# ADSP-2183xW_HPC register map
Vendor: Analog Devices; Series: ADSP-2183xW_HPC; File version: 3.0.3.517
CPU: 
Registers are 32-bit, read-write, reset 0x0 unless marked. A register's access mark holds for its fields unless they carry their own. Offsets are from the block's base; [hi:lo] are bit positions; {n}, {i} and the like mark numbered series.

## XSPI — Expanded Serial Peripheral Interface
Base 0x3101C000
{0x0+4i} CMD{i} (i=0..5) — Command Register {i}
  [31:0] VALUE range 0x00000000..0xFFFFFFFF — Command {i} Value
0x40 CMD_STAT_PTR — Command Status Pointer Register
  [2:0] THRD_SEL range 0x00000000..0x00000007 — Thread ID
0x44 CMD_STAT — Command Status Register
  [31:0] STAT ro — Command Status
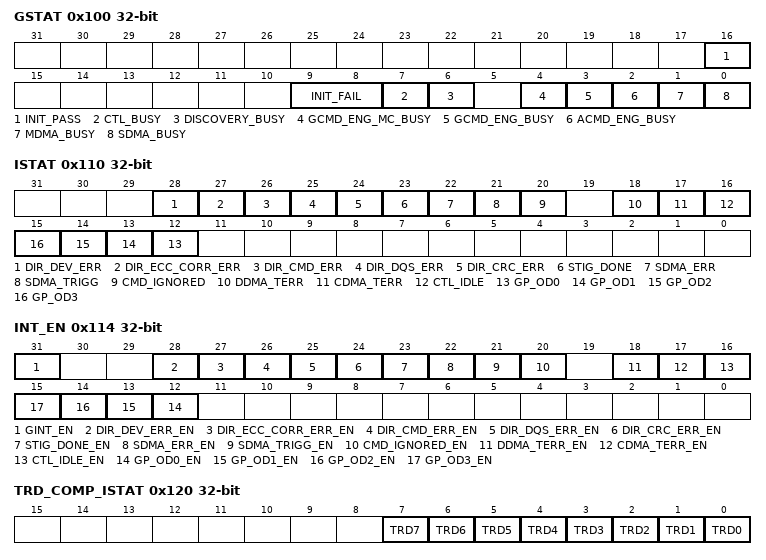
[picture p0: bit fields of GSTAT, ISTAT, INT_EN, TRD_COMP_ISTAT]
0x100 GSTAT — General Controller Status Register
  [16] INIT_PASS ro — Initialization Complete
  [9:8] INIT_FAIL ro — Initialization Status
  [7] CTL_BUSY ro — Controller Busy
  [6] DISCOVERY_BUSY ro
  [4] GCMD_ENG_MC_BUSY ro — GCMD Engine MC Busy
  [3] GCMD_ENG_BUSY ro — GCMD Engine Busy
  [2] ACMD_ENG_BUSY ro — ACMD Engine Busy
  [1] MDMA_BUSY ro
  [0] SDMA_BUSY ro
0x104 TRD_STAT — Auto Command Engine Thread Status Register
  [7:0] TRD_BUSY ro — Thread ID Busy
0x110 ISTAT — Interrupt Status Register
  [28] DIR_DEV_ERR range 0x00000000..0x00000001 — Device Return or Uncorrectable ECC Error
  [27] DIR_ECC_CORR_ERR range 0x00000000..0x00000001 — Correctable ECC Error
  [26] DIR_CMD_ERR range 0x00000000..0x00000001 — Command Error
  [25] DIR_DQS_ERR range 0x00000000..0x00000001 — DQS Error
  [24] DIR_CRC_ERR range 0x00000000..0x00000001 — CRC Error
  [23] STIG_DONE range 0x00000000..0x00000001
  [22] SDMA_ERR range 0x00000000..0x00000001 — SDMA Error
  [21] SDMA_TRIGG range 0x00000000..0x00000001 — SDMA Trigger
  [20] CMD_IGNORED range 0x00000000..0x00000001 — Command Ignored
  [18] DDMA_TERR range 0x00000000..0x00000001 — Master Data DMA Error
  [17] CDMA_TERR range 0x00000000..0x00000001 — Command DMA Error
  [16] CTL_IDLE range 0x00000000..0x00000001 — xSPI Controller Idle
  [n+12] GP_OD{n} range 0x00000000..0x00000001 (n=0..3) — GP OD{n} Transition Status
0x114 INT_EN — Interrupt Enable Register
  [31] GINT_EN range 0x00000000..0x00000001 — Global Interrupt Enable Flag
  [28] DIR_DEV_ERR_EN range 0x00000000..0x00000001 — Interrupt Enable for Uncorrectable ECC Error
  [27] DIR_ECC_CORR_ERR_EN range 0x00000000..0x00000001 — Interrupt Enable for Correctable ECC Error
  [26] DIR_CMD_ERR_EN range 0x00000000..0x00000001 — Interrupt Enable for Command Error
  [25] DIR_DQS_ERR_EN range 0x00000000..0x00000001 — Interrupt Enable for DQS Error
  [24] DIR_CRC_ERR_EN range 0x00000000..0x00000001 — Interrupt Enable for CRC Error
  [23] STIG_DONE_EN range 0x00000000..0x00000001 — Interrupt Enable for STIG Done
  [22] SDMA_ERR_EN range 0x00000000..0x00000001 — Interrupt Enable for SDMA Error
  [21] SDMA_TRIGG_EN range 0x00000000..0x00000001 — Interrupt Enable for SDMA Trigger
  [20] CMD_IGNORED_EN range 0x00000000..0x00000001 — Interrupt Enable for Ignored Command
  [18] DDMA_TERR_EN range 0x00000000..0x00000001 — Interrupt Enable for Data DMA Error
  [17] CDMA_TERR_EN range 0x00000000..0x00000001 — Interrupt Enable for Command DMA Error
  [16] CTL_IDLE_EN range 0x00000000..0x00000001 — Interrupt Enable for Idle State
  [n+12] GP_OD{n}_EN range 0x00000000..0x00000001 (n=0..3) — Interrupt Enable for GP OD{n} Transition
0x120 TRD_COMP_ISTAT — Auto Command Engine Interrupt Status Thread Register
  [n] TRD{n} range 0x00000000..0x00000001 (n=0..7) — Thread {n} Operation Complete
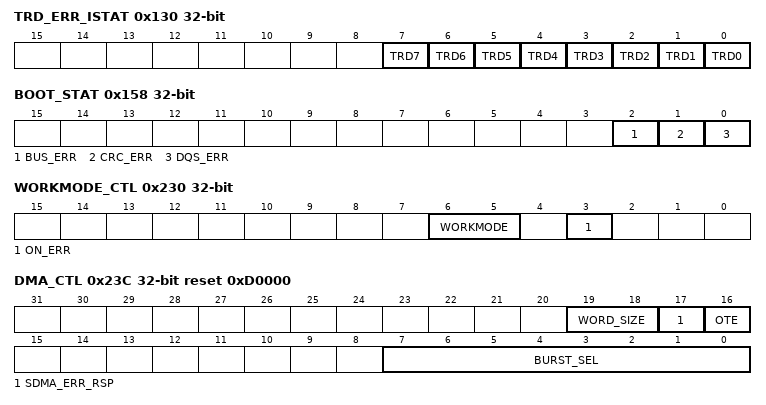
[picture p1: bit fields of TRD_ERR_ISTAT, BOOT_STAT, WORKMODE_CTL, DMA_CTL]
0x130 TRD_ERR_ISTAT — Thread Error Interrupt Status Register
  [n] TRD{n} range 0x00000000..0x00000001 (n=0..7) — Thread {n} Error
0x134 TRD_ERR_INT_EN — Thread Error Interrupt Enable Register
  [7:0] TRD_ERR_INT_EN range 0x00000000..0x000000FF — Interrupt Enable for Thread Error
0x150 DMA_ERRADDR_LO — DMA Error Address Low Register
  [31:0] VALUE ro — Low Address Value
0x154 DMA_ERRADDR_HI — DMA Error Address High Register
  [31:0] VALUE ro — High Address Value
0x158 BOOT_STAT — Boot Status Register
  [2] BUS_ERR ro — Bus Error Status
    0=BUSNOERROR (No Error Detected); 1=BUSERROR (Error Detected)
  [1] CRC_ERR ro — CRC Error Status
    0=CRCNOERROR (No Error Detected); 1=CRCERROR (Error Detected)
  [0] DQS_ERR ro — DQS Error Status
    0=DQSNOERROR (No Error Detected); 1=DQSERROR (Error Detected)
0x208 LONGPOL_GCTL reset 0x3E8 — Long Polling Count Register
  [15:0] VALUE range 0x00000000..0x0000FFFF — Long Poll Value
0x20C SHORTPOL_GCTL reset 0x1F4 — Short Polling Count Register
  [15:0] VALUE range 0x00000000..0x0000FFFF — Short Poll Value
0x230 WORKMODE_CTL — Device Control Register
  [6:5] WORKMODE range 0x00000000..0x00000003 — Controller Work Mode
  [3] ON_ERR range 0x00000000..0x00000001 — Controller On Error
0x23C DMA_CTL reset 0xD0000 — DMA Interface Control Register
  [19:18] WORD_SIZE — DMA Word Size
  [17] SDMA_ERR_RSP range 0x00000000..0x00000001 — SDMA Error Response
  [16] OTE range 0x00000000..0x00000001 — Outstanding Transaction Enable
  [7:0] BURST_SEL range 0x00000000..0x000000FF — Burst Size
0x240 SDMA_SIZ — Host DMA Block Size Register
  [31:0] VALUE ro — SDMA Block Size
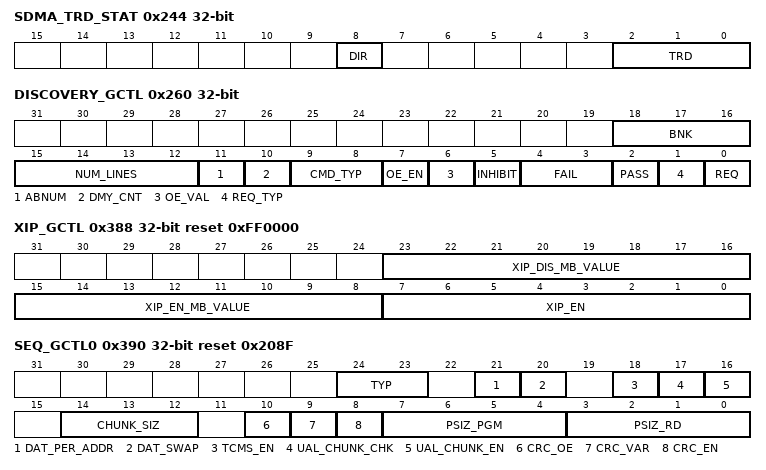
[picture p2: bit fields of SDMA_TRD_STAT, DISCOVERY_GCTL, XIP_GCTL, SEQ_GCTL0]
0x244 SDMA_TRD_STAT — Host DMA Thread Status Register
  [8] DIR ro — DMA Direction
  [2:0] TRD ro — Thread ID
0x24C SDMA_ADDR0 — Host DMA Buffer Address Register 0
  [31:0] LO_VALUE ro — Low Address Value
0x250 SDMA_ADDR1 — Host DMA Buffer Address Register 1
  [31:0] HI_VALUE ro — High Address Value
0x260 DISCOVERY_GCTL — Device Discovery Control Register
  [18:16] BNK range 0x00000000..0x00000007 — Discovery Bank Select
  [15:12] NUM_LINES — Discovery IO Number of Lines
  [11] ABNUM — Discovery Number Address
  [10] DMY_CNT — Discovery Dummy Clock Cycles Count
  [9:8] CMD_TYP — Discovery Command Type Mode Enable
  [7] OE_EN — Discovery Extended Opcode Enable
  [6] OE_VAL — Discovery Extended Opcode Value
  [5] INHIBIT ro — Discovery Inhibit Status
  [4:3] FAIL ro — Result of Last Discovery Operation
  [2] PASS ro — Status of Last Discovery Operation
  [1] REQ_TYP — Discovery Request Type
  [0] REQ range 0x00000000..0x00000001 — Discovery Request
0x388 XIP_GCTL reset 0xFF0000 — XIP Configuration Register
  [23:16] XIP_DIS_MB_VALUE range 0x00000000..0x000000FF — XIP Mode Bit Disable Value
  [15:8] XIP_EN_MB_VALUE range 0x00000000..0x000000FF — XIP Mode Bit Enable Value
  [7:0] XIP_EN range 0x00000000..0x000000FF — XIP Mode Enable
0x390 SEQ_GCTL0 reset 0x208F — Sequence Configuration Register 0
  [24:23] TYP — Sequence Type
  [21] DAT_PER_ADDR — Data Bytes per Address
  [20] DAT_SWAP — Enable Reversed Byte Order
  [18] TCMS_EN — Enable TCMS Timing in Profile 1
  [17] UAL_CHUNK_CHK — Enable CRC Checking of Unaligned Chunk
  [16] UAL_CHUNK_EN — Enable CRC Chunk
  [14:12] CHUNK_SIZ — Chunk Size
  [10] CRC_OE
  [9] CRC_VAR — Select CRC Variant
  [8] CRC_EN — Enable CRC
  [7:4] PSIZ_PGM range 0x00000000..0x0000000F — Device Page Program Size
  [3:0] PSIZ_RD range 0x00000000..0x0000000F — Device Page Read Size
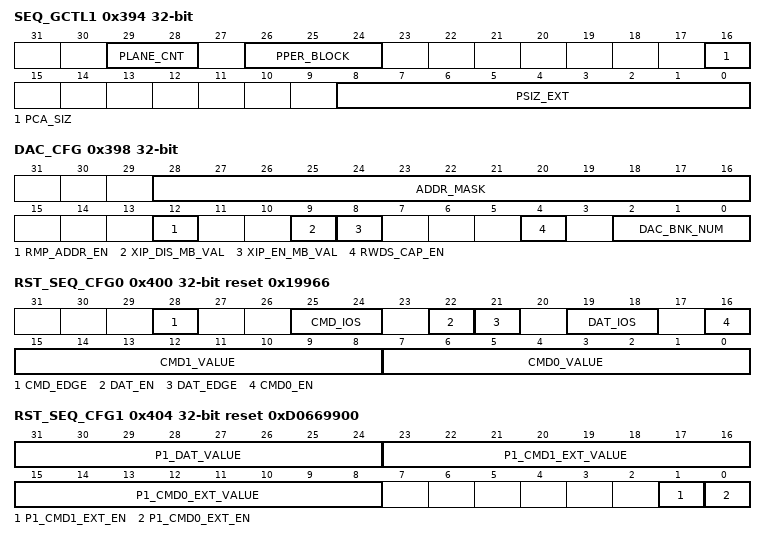
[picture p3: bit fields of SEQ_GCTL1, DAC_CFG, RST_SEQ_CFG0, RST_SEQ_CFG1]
0x394 SEQ_GCTL1 — Sequence Configuration Register 1
  [29:28] PLANE_CNT — Plane Count
  [26:24] PPER_BLOCK — Pages per Block
  [16] PCA_SIZ — Column Address Width
  [8:0] PSIZ_EXT range 0x00000000..0x000001FF — Extended Page Size
0x398 DAC_CFG — DAC Configuration Register
  [28:16] ADDR_MASK range 0x00000000..0x00001FFF — Profile 2 Address Mask
  [12] RMP_ADDR_EN range 0x00000000..0x00000001 — Enable Host Data Interface Address Remapping
  [9] XIP_DIS_MB_VAL range 0x00000000..0x00000001 — XIP Mode Disable
  [8] XIP_EN_MB_VAL range 0x00000000..0x00000001 — XIP Mode Enable
  [4] RWDS_CAP_EN range 0x00000000..0x00000001 — RWDS Byte Mask Enable
  [2:0] DAC_BNK_NUM range 0x00000000..0x00000007 — Bank Number
0x39C DAC_REMAPADDR0 — Address Remapping Register 0
  [31:0] ADDR_VALUE0 range 0x00000000..0xFFFFFFFF — Remapping Address Low
0x3A0 DAC_REMAPADDR1 — Address Remapping Register 1
  [31:0] ADDR_VALUE1 range 0x00000000..0xFFFFFFFF — Remapping Address High
0x400 RST_SEQ_CFG0 reset 0x19966 — Reset Sequence Configuration Register 0
  [28] CMD_EDGE range 0x00000000..0x00000001 — Command Phase SDR/DDR Select
  [25:24] CMD_IOS — Command Phase IO Lines Select
  [22] DAT_EN range 0x00000000..0x00000001 — Enable Data Phase
  [21] DAT_EDGE range 0x00000000..0x00000001 — Data Phase SDR/DDR Select
  [19:18] DAT_IOS — Data Phase IO Lines Selection
  [16] CMD0_EN range 0x00000000..0x00000001 — Enable Command 0 Phase
  [15:8] CMD1_VALUE range 0x00000000..0x000000FF — Command 1 Opcode
  [7:0] CMD0_VALUE range 0x00000000..0x000000FF — Command 0 Opcode
0x404 RST_SEQ_CFG1 reset 0xD0669900 — Reset Sequence Configuration Register 1
  [31:24] P1_DAT_VALUE range 0x00000000..0x000000FF — Command 1 Confirmation
  [23:16] P1_CMD1_EXT_VALUE range 0x00000000..0x000000FF — Command 1 Opcode
  [15:8] P1_CMD0_EXT_VALUE range 0x00000000..0x000000FF — Command 0 Opcode
  [1] P1_CMD1_EXT_EN range 0x00000000..0x00000001 — Enable Command 1
  [0] P1_CMD0_EXT_EN range 0x00000000..0x00000001 — Enable Command 0
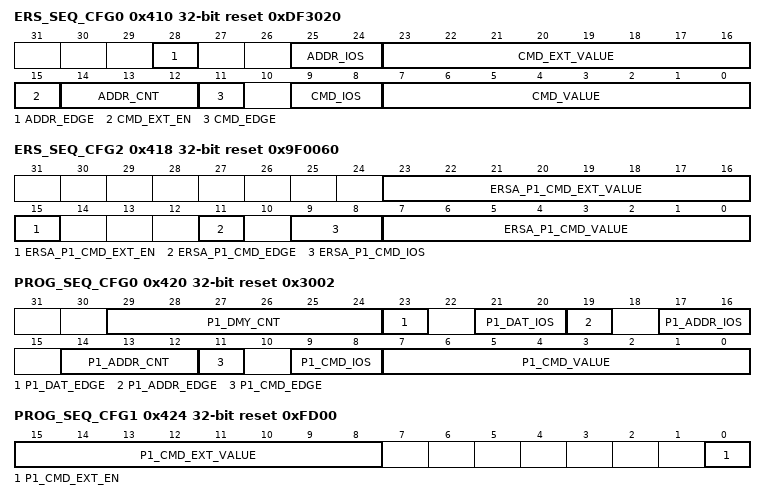
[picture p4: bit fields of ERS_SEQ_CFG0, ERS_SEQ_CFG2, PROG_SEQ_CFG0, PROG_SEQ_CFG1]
0x410 ERS_SEQ_CFG0 reset 0xDF3020 — Erase Sequence Configuration Register 0
  [28] ADDR_EDGE range 0x00000000..0x00000001 — Address Phase SDR/DDR Select
  [25:24] ADDR_IOS — Address Phase IO Lines Select
  [23:16] CMD_EXT_VALUE range 0x00000000..0x000000FF — Command Extension Value
  [15] CMD_EXT_EN range 0x00000000..0x00000001 — Enable Command Extension
  [14:12] ADDR_CNT range 0x00000000..0x00000007 — Address Byte Count
  [11] CMD_EDGE range 0x00000000..0x00000001 — Command Phase SDR/DDR Select
  [9:8] CMD_IOS — Command Phase IO Lines Select
  [7:0] CMD_VALUE range 0x00000000..0x000000FF — Command Mnemonic Value
0x414 ERS_SEQ_CFG1 reset 0xC — Erase Sequence Configuration Register 1
  [4:0] P1_SECT_SIZ_VALUE range 0x00000000..0x0000001F — Sector Size
0x418 ERS_SEQ_CFG2 reset 0x9F0060 — Erase Sequence Configuration Register 2
  [23:16] ERSA_P1_CMD_EXT_VALUE range 0x00000000..0x000000FF — Command Extension Value
  [15] ERSA_P1_CMD_EXT_EN range 0x00000000..0x00000001 — Enable Command Extension
  [11] ERSA_P1_CMD_EDGE range 0x00000000..0x00000001 — Command Phase SDR/DDR Select
  [9:8] ERSA_P1_CMD_IOS — Command Phase IO Lines Select
  [7:0] ERSA_P1_CMD_VALUE range 0x00000000..0x000000FF — Command Mnemonic Value
0x420 PROG_SEQ_CFG0 reset 0x3002 — Program Sequence Configuration Register 0
  [29:24] P1_DMY_CNT range 0x00000000..0x0000003F — Number of Dummy Cycle
  [23] P1_DAT_EDGE range 0x00000000..0x00000001 — Data Phase SDR/DDR Select
  [21:20] P1_DAT_IOS — Data Phase IO Line Select
  [19] P1_ADDR_EDGE range 0x00000000..0x00000001 — Address Phase SDR/DDR Select
  [17:16] P1_ADDR_IOS — Address Phase IO Line Select
  [14:12] P1_ADDR_CNT range 0x00000000..0x00000007 — Address Byte Count
  [11] P1_CMD_EDGE range 0x00000000..0x00000001 — Command Phase SDR/DDR Select
  [9:8] P1_CMD_IOS — Command Phase IO Line Select
  [7:0] P1_CMD_VALUE range 0x00000000..0x000000FF — Command Mnemonic Value
0x424 PROG_SEQ_CFG1 reset 0xFD00 — Program Sequence Configuration Register 1
  [15:8] P1_CMD_EXT_VALUE range 0x00000000..0x000000FF — Command Extension Value
  [0] P1_CMD_EXT_EN range 0x00000000..0x00000001 — Command Extension Enable
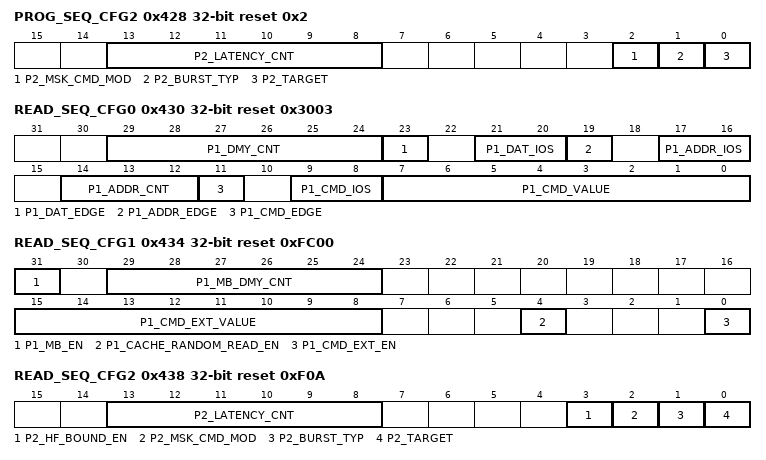
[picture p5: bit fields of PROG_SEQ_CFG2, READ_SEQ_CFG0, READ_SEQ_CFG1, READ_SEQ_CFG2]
0x428 PROG_SEQ_CFG2 reset 0x2 — Program Sequence Configuration Register 2
  [13:8] P2_LATENCY_CNT range 0x00000000..0x0000003F — Number of Latency Cycles
  [2] P2_MSK_CMD_MOD range 0x00000000..0x00000001 — Profile 2 Command Extension Mask/Mode
  [1] P2_BURST_TYP — Burst Type
  [0] P2_TARGET — Target Space
0x430 READ_SEQ_CFG0 reset 0x3003 — Read Sequence Configuration Register 0
  [29:24] P1_DMY_CNT range 0x00000000..0x0000003F — Number of Dummy Cycles
  [23] P1_DAT_EDGE range 0x00000000..0x00000001 — Data Phase SDR/DDR Select
  [21:20] P1_DAT_IOS — Data Phase IO Line Select
  [19] P1_ADDR_EDGE range 0x00000000..0x00000001 — Address Phase SDR/DDR Select
  [17:16] P1_ADDR_IOS — Address Phase IO Lines Select
  [14:12] P1_ADDR_CNT range 0x00000000..0x00000007 — Number of Address Bytes
  [11] P1_CMD_EDGE range 0x00000000..0x00000001 — Command Phase SDR/DDR Select
  [9:8] P1_CMD_IOS — Command Phase IO Lines Select
  [7:0] P1_CMD_VALUE range 0x00000000..0x000000FF — Command Mnemonic Value
0x434 READ_SEQ_CFG1 reset 0xFC00 — Read Sequence Configuration Register 1
  [31] P1_MB_EN range 0x00000000..0x00000001 — Mode Bit Enable
  [29:24] P1_MB_DMY_CNT range 0x00000000..0x0000003F — Number of dummy cycles
  [15:8] P1_CMD_EXT_VALUE range 0x00000000..0x000000FF — Command Extension Value
  [4] P1_CACHE_RANDOM_READ_EN range 0x00000000..0x00000001 — Random Cache Read Enable
  [0] P1_CMD_EXT_EN range 0x00000000..0x00000001 — Enables Command Extension
0x438 READ_SEQ_CFG2 reset 0xF0A — Read Sequence Configuration Register 2
  [13:8] P2_LATENCY_CNT range 0x00000000..0x0000003F — Number of Latency Cycles
  [3] P2_HF_BOUND_EN — Enable Read Operation Page Boundary
  [2] P2_MSK_CMD_MOD range 0x00000000..0x00000001 — Profile 2 Command Extension Mask/Mode
  [1] P2_BURST_TYP — Burst Type
  [0] P2_TARGET — Target Space
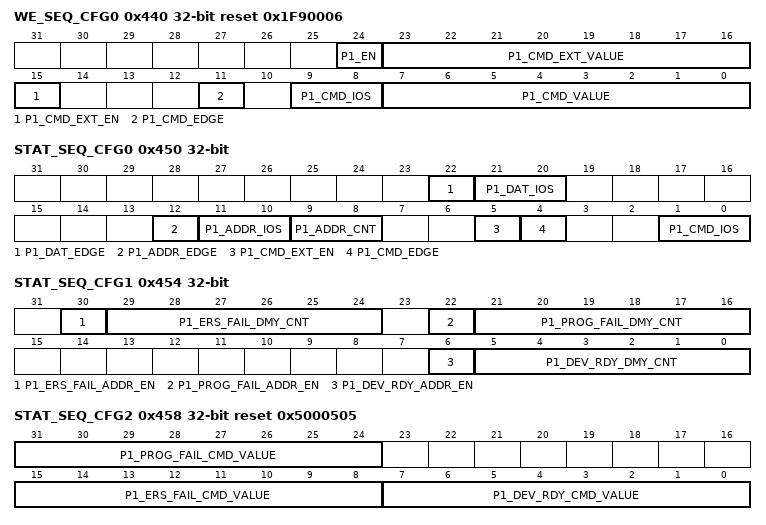
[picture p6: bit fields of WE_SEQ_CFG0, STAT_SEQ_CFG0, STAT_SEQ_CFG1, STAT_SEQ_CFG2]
0x440 WE_SEQ_CFG0 reset 0x1F90006 — WEL Sequence Configuration Register
  [24] P1_EN range 0x00000000..0x00000001 — Enable WEL Command
  [23:16] P1_CMD_EXT_VALUE range 0x00000000..0x000000FF — Command Extension Value
  [15] P1_CMD_EXT_EN range 0x00000000..0x00000001 — Command Extension Enable
  [11] P1_CMD_EDGE range 0x00000000..0x00000001 — Command Phase SDR/DDR Select
  [9:8] P1_CMD_IOS — Command Phase IO Lines Select
  [7:0] P1_CMD_VALUE range 0x00000000..0x000000FF — Command Mnemonic Value
0x450 STAT_SEQ_CFG0 — Status Checking Sequence Configuration Register 0
  [22] P1_DAT_EDGE range 0x00000000..0x00000001 — Data Phase SDR/DDR Select
  [21:20] P1_DAT_IOS — Data Phase IO Lines Select
  [12] P1_ADDR_EDGE range 0x00000000..0x00000001 — Address Phase SDR/DDR Select
  [11:10] P1_ADDR_IOS — Address Phase IO Lines Select
  [9:8] P1_ADDR_CNT — Number of Address Bytes
  [5] P1_CMD_EXT_EN range 0x00000000..0x00000001 — Command Extension Enable
  [4] P1_CMD_EDGE range 0x00000000..0x00000001 — Command Phase SDR/DDR Select
  [1:0] P1_CMD_IOS — Command Phase IO Lines Select
0x454 STAT_SEQ_CFG1 — Status Checking Sequence Configuration Register 1
  [30] P1_ERS_FAIL_ADDR_EN range 0x00000000..0x00000001 — Enable Address Phase
  [29:24] P1_ERS_FAIL_DMY_CNT range 0x00000000..0x0000003F — Number of Dummy Clock Cycles
  [22] P1_PROG_FAIL_ADDR_EN range 0x00000000..0x00000001 — Enable Address Phase
  [21:16] P1_PROG_FAIL_DMY_CNT range 0x00000000..0x0000003F — Number of Dummy Clock Cycles
  [6] P1_DEV_RDY_ADDR_EN range 0x00000000..0x00000001 — Enable Address Phase
  [5:0] P1_DEV_RDY_DMY_CNT range 0x00000000..0x0000003F — Number of Dummy Clock Cycles
0x458 STAT_SEQ_CFG2 reset 0x5000505 — Status Checking Sequence Configuration Register 2
  [31:24] P1_PROG_FAIL_CMD_VALUE range 0x00000000..0x000000FF — Program Opcode
  [15:8] P1_ERS_FAIL_CMD_VALUE range 0x00000000..0x000000FF — Erase Opcode
  [7:0] P1_DEV_RDY_CMD_VALUE range 0x00000000..0x000000FF — Ready Busy Opcode
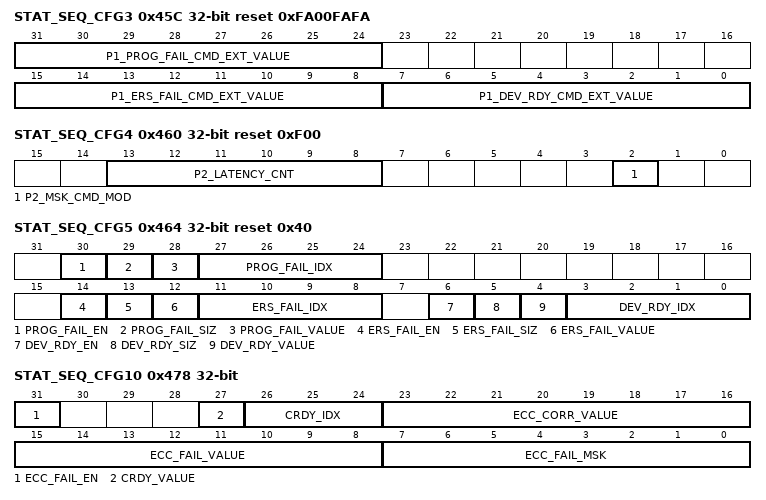
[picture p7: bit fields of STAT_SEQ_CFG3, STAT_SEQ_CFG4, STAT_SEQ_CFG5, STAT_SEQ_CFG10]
0x45C STAT_SEQ_CFG3 reset 0xFA00FAFA — Status Checking Sequence Configuration Register 3
  [31:24] P1_PROG_FAIL_CMD_EXT_VALUE range 0x00000000..0x000000FF — Program Opcode Extension
  [15:8] P1_ERS_FAIL_CMD_EXT_VALUE range 0x00000000..0x000000FF — Erase Opcode Extension
  [7:0] P1_DEV_RDY_CMD_EXT_VALUE range 0x00000000..0x000000FF — Ready Busy Opcode Extension
0x460 STAT_SEQ_CFG4 reset 0xF00 — Status Checking Sequence Configuration Register 4
  [13:8] P2_LATENCY_CNT range 0x00000000..0x0000003F — Latency Between CA and Status Reading
  [2] P2_MSK_CMD_MOD range 0x00000000..0x00000001 — Profile 2 Command Extension Mask/Mode
0x464 STAT_SEQ_CFG5 reset 0x40 — Status Checking Sequence Configuration Register 5
  [30] PROG_FAIL_EN range 0x00000000..0x00000001 — Enable Failure Check after Program
  [29] PROG_FAIL_SIZ range 0x00000000..0x00000001 — Size of Status Word
  [28] PROG_FAIL_VALUE range 0x00000000..0x00000001 — Value to Compare with Status Word
  [27:24] PROG_FAIL_IDX range 0x00000000..0x0000000F — Failure Info in Status Word
  [14] ERS_FAIL_EN range 0x00000000..0x00000001 — Enable Failure Check after Erase
  [13] ERS_FAIL_SIZ range 0x00000000..0x00000001 — Size of Status Word
  [12] ERS_FAIL_VALUE range 0x00000000..0x00000001 — Value to Compare with Status Word
  [11:8] ERS_FAIL_IDX range 0x00000000..0x0000000F — Failure Info in Status Word
  [6] DEV_RDY_EN range 0x00000000..0x00000001 — Enable RDY/BUSY Status
  [5] DEV_RDY_SIZ range 0x00000000..0x00000001 — Size of Status Word
  [4] DEV_RDY_VALUE range 0x00000000..0x00000001 — Value to Compare Status Word
  [3:0] DEV_RDY_IDX range 0x00000000..0x0000000F — Ready Busy in Status Word
0x46C STAT_SEQ_CFG7 — Status Checking Sequence Configuration Register 7
  [31:0] DEV_RDY_ADDR_VALUE range 0x00000000..0xFFFFFFFF — Address to Check READY/BUSY Status
0x470 STAT_SEQ_CFG8 — Status Checking Sequence Configuration Register 8
  [31:0] PROG_FAIL_ADDR_VALUE range 0x00000000..0xFFFFFFFF — Address to Check Failure Status after Program
0x474 STAT_SEQ_CFG9 — Status Checking Sequence Configuration Register 9
  [31:0] ERS_FAIL_ADDR_VALUE range 0x00000000..0xFFFFFFFF — Address to Check Failure Status after Erase
0x478 STAT_SEQ_CFG10 — Status Checking Sequence Configuration Register 10
  [31] ECC_FAIL_EN range 0x00000000..0x00000001 — Enable ECC Status Check
  [27] CRDY_VALUE range 0x00000000..0x00000001 — Value to Compare with Status Word
  [26:24] CRDY_IDX range 0x00000000..0x00000007 — CRBSY Info in Status Word
  [23:16] ECC_CORR_VALUE range 0x00000000..0x000000FF — Value to Compare with Status Word
  [15:8] ECC_FAIL_VALUE range 0x00000000..0x000000FF — Value to Compare with Status Word
  [7:0] ECC_FAIL_MSK range 0x00000000..0x000000FF — ECC Mask
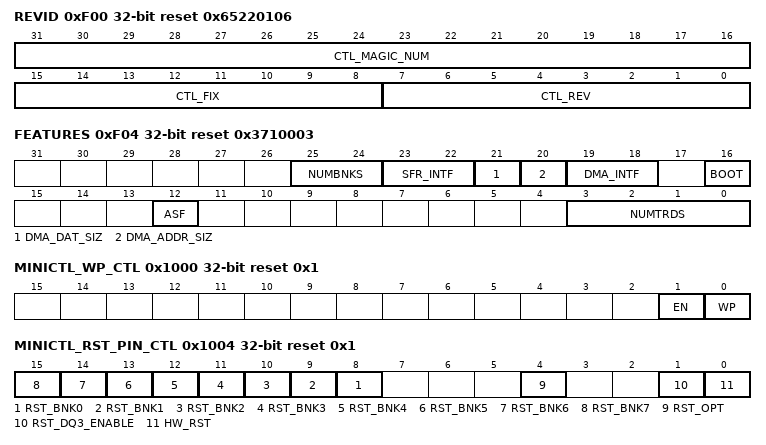
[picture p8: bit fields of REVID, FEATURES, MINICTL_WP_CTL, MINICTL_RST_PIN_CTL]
0xF00 REVID reset 0x65220106 — Revision ID Register
  [31:16] CTL_MAGIC_NUM ro — Magic Number
  [15:8] CTL_FIX ro — Fixed Number
  [7:0] CTL_REV ro — Controller Revision
0xF04 FEATURES reset 0x3710003 — Controller Features Register
  [25:24] NUMBNKS ro — Max Banks Supported
  [23:22] SFR_INTF ro — SFR Interface Type
  [21] DMA_DAT_SIZ ro — Host DMA Data Width
  [20] DMA_ADDR_SIZ ro — Host DMA Address Width
  [19:18] DMA_INTF ro — DMA Interface Type
  [16] BOOT ro — Boot Feature Present
  [12] ASF ro — ASF Feature Present
  [3:0] NUMTRDS ro — Number of Threads Supported
0x1000 MINICTL_WP_CTL reset 0x1 — Write Protect Register
  [1] EN range 0x00000000..0x00000001 — Enable Write Protection
  [0] WP range 0x00000000..0x00000001 — Write Protect
0x1004 MINICTL_RST_PIN_CTL reset 0x1 — Hardware Reset Control Register
  [n+8] RST_BNK{n} (n=0..7) — Bank {n} Reset
  [4] RST_OPT — Hardware Reset
  [1] RST_DQ3_ENABLE range 0x00000000..0x00000001 — Enable DQ3 Reset
  [0] HW_RST range 0x00000000..0x00000001 — Software Controlled Hardware Reset
0x1008 MINICTL_CLKMODE — Clock Mode Control Register
  [0] VALUE range 0x00000000..0x00000001 — SPI Clock Mode Select
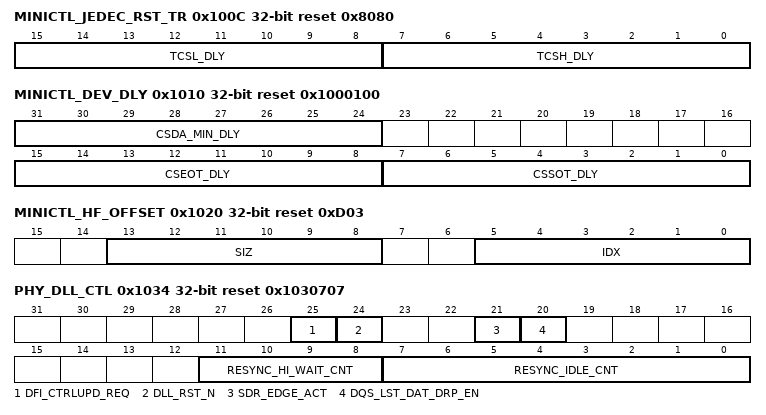
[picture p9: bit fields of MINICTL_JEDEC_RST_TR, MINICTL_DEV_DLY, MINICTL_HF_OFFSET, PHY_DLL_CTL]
0x100C MINICTL_JEDEC_RST_TR reset 0x8080 — JEDEC Reset Delay Register
  [15:8] TCSL_DLY range 0x00000000..0x000000FF — TCSL Timing Configuration
  [7:0] TCSH_DLY range 0x00000000..0x000000FF — TCSH Timing Configuration
0x1010 MINICTL_DEV_DLY reset 0x1000100 — Device Delay Register
  [31:24] CSDA_MIN_DLY range 0x00000000..0x000000FF — Minimum Chip Select Deassertion
  [15:8] CSEOT_DLY range 0x00000000..0x000000FF — Chip Select End Of Transfer
  [7:0] CSSOT_DLY range 0x00000000..0x000000FF — Chip Select Start Of Transfer
0x1014 MINICTL_RST_RECOV reset 0xA — Reset Recovery Delay Register
  [31:0] VALUE range 0x00000000..0xFFFFFFFF — Additional Delay for CS Deassertion
0x1018 MINICTL_DEV_ACTIVE_MAX reset 0x80 — Device Active Maximum Clock Cycle Register
  [31:0] VALUE range 0x00000000..0xFFFFFFFF
0x1020 MINICTL_HF_OFFSET reset 0xD03 — HyperFlash Offset Register
  [13:8] SIZ range 0x00000000..0x0000003F — Offset Size
  [5:0] IDX range 0x00000000..0x0000003F — Start Index
0x1030 PHY_DLL_UPDT_CNT — PHY DLL Resynchronization Register
  [31:0] RESYNC_CNT range 0x00000000..0xFFFFFFFF — Resynchronization of slave DLL of PHY
0x1034 PHY_DLL_CTL reset 0x1030707 — PHY DLL Control Register
  [25] DFI_CTRLUPD_REQ range 0x00000000..0x00000001 — Resynchronize DLLs
  [24] DLL_RST_N range 0x00000000..0x00000001 — DLL Reset
  [21] SDR_EDGE_ACT range 0x00000000..0x00000001 — SDR Mode Edge Active
  [20] DQS_LST_DAT_DRP_EN range 0x00000000..0x00000001 — Enable DQS Last Data Drop
  [11:8] RESYNC_HI_WAIT_CNT range 0x00000000..0x0000000F — DLL Update Wait Count
  [7:0] RESYNC_IDLE_CNT range 0x00000000..0x000000FF — DLL Update Wait Time
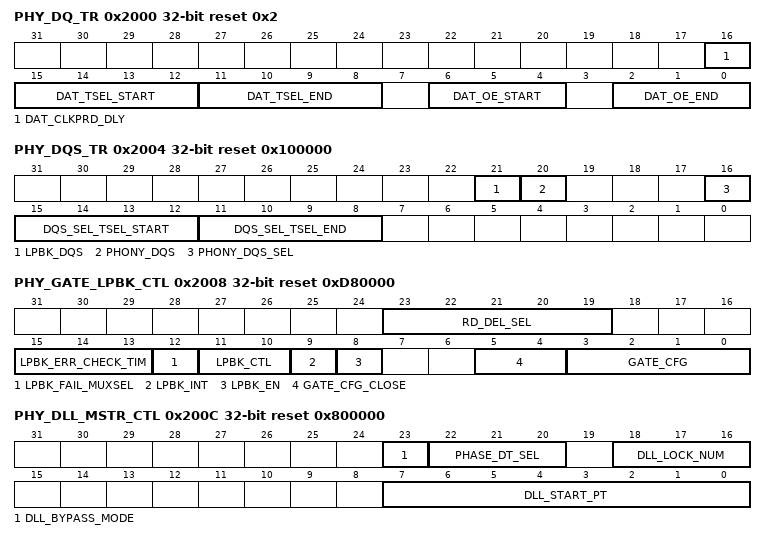
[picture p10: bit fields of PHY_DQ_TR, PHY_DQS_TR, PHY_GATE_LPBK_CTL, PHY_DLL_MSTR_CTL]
0x2000 PHY_DQ_TR reset 0x2 — PHY DQ Timing Register
  [16] DAT_CLKPRD_DLY range 0x00000000..0x00000001 — Write Data Path Additional Latency
  [15:12] DAT_TSEL_START range 0x00000000..0x0000000F — DQ Pad Time Delay Enable
  [11:8] DAT_TSEL_END range 0x00000000..0x0000000F — DQ Pad Disable Time Delay Cycle
  [6:4] DAT_OE_START range 0x00000000..0x00000007 — DQ Pad OE Window Start Point
  [2:0] DAT_OE_END range 0x00000000..0x00000007 — DQ Pad OE Window End Point
0x2004 PHY_DQS_TR reset 0x100000 — PHY DQS Timing Register
  [21] LPBK_DQS range 0x00000000..0x00000001 — Internal Loop Back Configuration
  [20] PHONY_DQS — DQS Mode Configuration
  [16] PHONY_DQS_SEL range 0x00000000..0x00000001 — PHONY DQS Configuration
  [15:12] DQS_SEL_TSEL_START range 0x00000000..0x0000000F — DQ Pad Termination Select Enable Time
  [11:8] DQS_SEL_TSEL_END range 0x00000000..0x0000000F — DQ Pad Termination Select Disable Time
0x2008 PHY_GATE_LPBK_CTL reset 0xD80000 — PHY Gate Loopback Control Register
  [23:19] RD_DEL_SEL range 0x00000000..0x0000001F — Read Data Delay
  [15:13] LPBK_ERR_CHECK_TIM range 0x00000000..0x00000007 — Loopback Error Check
  [12] LPBK_FAIL_MUXSEL — Data Output
  [11:10] LPBK_CTL — Loopback Control
  [9] LPBK_INT — Loopback Multiplexer
  [8] LPBK_EN — Loopback Enable
  [5:4] GATE_CFG_CLOSE range 0x00000000..0x00000003 — Gate Close
  [3:0] GATE_CFG range 0x00000000..0x0000000F — Gate Open Time
0x200C PHY_DLL_MSTR_CTL reset 0x800000 — Master DLL Control Register
  [23] DLL_BYPASS_MODE — Master DLL Mode Enable
  [22:20] PHASE_DT_SEL — Phase Detect Delay
  [18:16] DLL_LOCK_NUM range 0x00000000..0x00000007 — DLL Lock Number
  [7:0] DLL_START_PT range 0x00000000..0x000000FF — Initial Delay Start
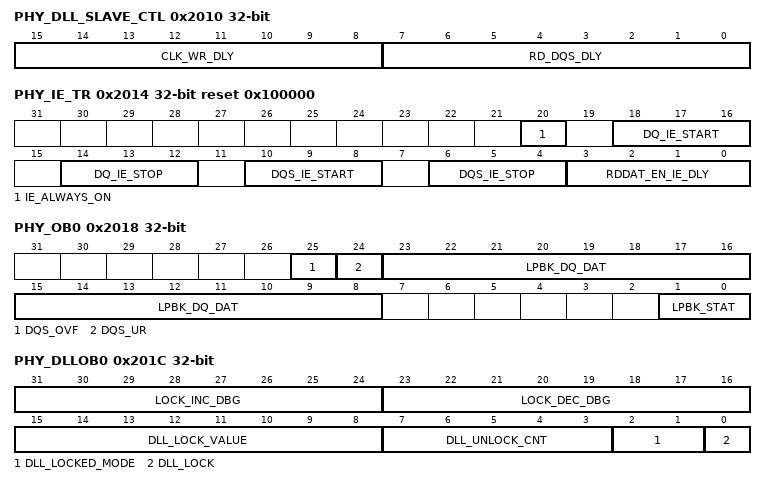
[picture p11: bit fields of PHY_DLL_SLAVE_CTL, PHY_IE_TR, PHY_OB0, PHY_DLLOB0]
0x2010 PHY_DLL_SLAVE_CTL — Slave DLL Control Register
  [15:8] CLK_WR_DLY range 0x00000000..0x000000FF — Clock Write Delay
  [7:0] RD_DQS_DLY range 0x00000000..0x000000FF — DQS Read Delay
0x2014 PHY_IE_TR reset 0x100000 — PHY DQS Input Enable Timing Register
  [20] IE_ALWAYS_ON range 0x00000000..0x00000001 — Input Enable Always On
  [18:16] DQ_IE_START range 0x00000000..0x00000007 — DQ Input Enable Start
  [14:12] DQ_IE_STOP range 0x00000000..0x00000007 — DQ Input Enable Stop
  [10:8] DQS_IE_START range 0x00000000..0x00000007 — DQS Input Enable Start
  [6:4] DQS_IE_STOP range 0x00000000..0x00000007 — DQS Input Enable Stop
  [3:0] RDDAT_EN_IE_DLY range 0x00000000..0x0000000F — Internal Read Data Enable delay
0x2018 PHY_OB0 — PHY Observable Points Register
  [25] DQS_OVF ro — DQS Overflow Error
  [24] DQS_UR ro — DQS Underrun Error
  [23:8] LPBK_DQ_DAT ro — Loopback Error
  [1:0] LPBK_STAT ro — Loopback Status
0x201C PHY_DLLOB0 — PHY DLL Observable Points 0 Register
  [31:24] LOCK_INC_DBG ro — DLL Lock Increment State
  [23:16] LOCK_DEC_DBG ro — DLL Lock Decrement State
  [15:8] DLL_LOCK_VALUE ro — DLL Lock Delays
  [7:3] DLL_UNLOCK_CNT ro — DLL Unlock Count
  [2:1] DLL_LOCKED_MODE ro — DLL Lock Mode
  [0] DLL_LOCK ro — DLL Lock Status
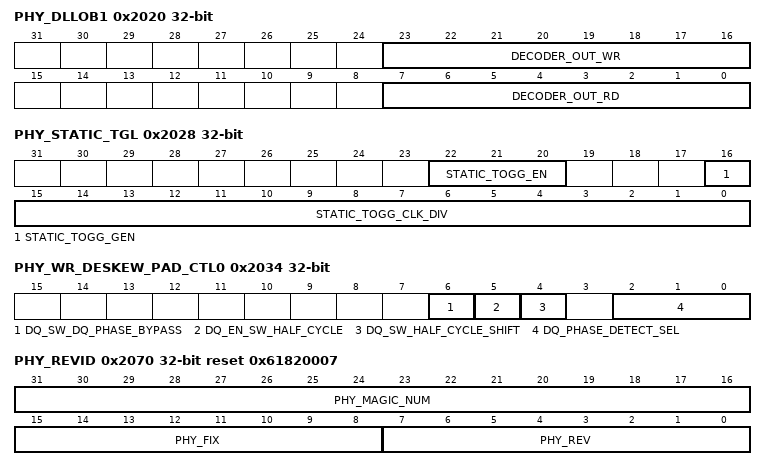
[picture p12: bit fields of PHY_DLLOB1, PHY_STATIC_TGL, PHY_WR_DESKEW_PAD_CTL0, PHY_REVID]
0x2020 PHY_DLLOB1 — PHY DLL Observable Points 1 Register
  [23:16] DECODER_OUT_WR ro — Write Encoded Value
  [7:0] DECODER_OUT_RD ro — Read Encoded Value
0x2028 PHY_STATIC_TGL — PHY Static Aging Register
  [22:20] STATIC_TOGG_EN range 0x00000000..0x00000007 — Static Toggle Enable
  [16] STATIC_TOGG_GEN range 0x00000000..0x00000001 — Global Static Toggle Enable
  [15:0] STATIC_TOGG_CLK_DIV range 0x00000000..0x0000FFFF — Clock Divider
0x2034 PHY_WR_DESKEW_PAD_CTL0 — PHY Deskew Write Register
  [6] DQ_SW_DQ_PHASE_BYPASS — DQ Phase Detect
  [5] DQ_EN_SW_HALF_CYCLE — Half Cycle Shift Enable
  [4] DQ_SW_HALF_CYCLE_SHIFT — Half Clock Delay Enable
  [2:0] DQ_PHASE_DETECT_SEL — DLL Phase Detect Select
0x2070 PHY_REVID reset 0x61820007 — PHY Revision ID Register
  [31:16] PHY_MAGIC_NUM ro — Magic Number
  [15:8] PHY_FIX ro — Fixed number
  [7:0] PHY_REV ro — PHY Revision
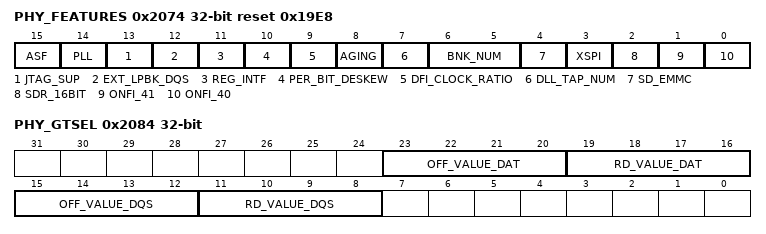
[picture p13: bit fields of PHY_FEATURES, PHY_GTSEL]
0x2074 PHY_FEATURES reset 0x19E8
  [15] ASF ro — Automotive Safety
  [14] PLL ro
  [13] JTAG_SUP ro — JTAG
  [12] EXT_LPBK_DQS ro — External Loopback DQS
  [11] REG_INTF ro — SFR Interface
  [10] PER_BIT_DESKEW ro
  [9] DFI_CLOCK_RATIO ro
  [8] AGING ro
  [7] DLL_TAP_NUM ro — Number of Taps in Delay
  [6:5] BNK_NUM ro — Max Banks
  [4] SD_EMMC ro
  [3] XSPI ro
  [2] SDR_16BIT ro — 16-Bit SDR
  [1] ONFI_41 ro
  [0] ONFI_40 ro
0x2080 PHY_GCTL reset 0x180 — PHY Global Control Register
  [0] CTL_CLKPRD_DLY range 0x00000000..0x00000001 — Control Latency
0x2084 PHY_GTSEL — PHY Global Termination Control Register
  [23:20] OFF_VALUE_DAT range 0x00000000..0x0000000F — Termination Select Off Data
  [19:16] RD_VALUE_DAT range 0x00000000..0x0000000F — Termination Select Read Data
  [15:12] OFF_VALUE_DQS range 0x00000000..0x0000000F — Termination Select Off Data Strobe
  [11:8] RD_VALUE_DQS range 0x00000000..0x0000000F — Termination Select Read Data Strobe
0x2088 PHY_GPIO_CTL0 — PHY GPIO Control Register 0
  [31:0] VALUE range 0x00000000..0xFFFFFFFF — GPIO Control Value 0
0x208C PHY_GPIO_CTL1 — PHY GPIO Control Register 1
  [31:0] VALUE range 0x00000000..0xFFFFFFFF — GPIO Control Value 1
0x2090 PHY_GPIO_STAT0 — PHY GPIO Status Register 0
  [31:0] VALUE ro — GPIO Status Value 0
0x2094 PHY_GPIO_STAT1 — PHY GPIO Status Register 1
  [31:0] VALUE ro — GPIO Status Value 1
